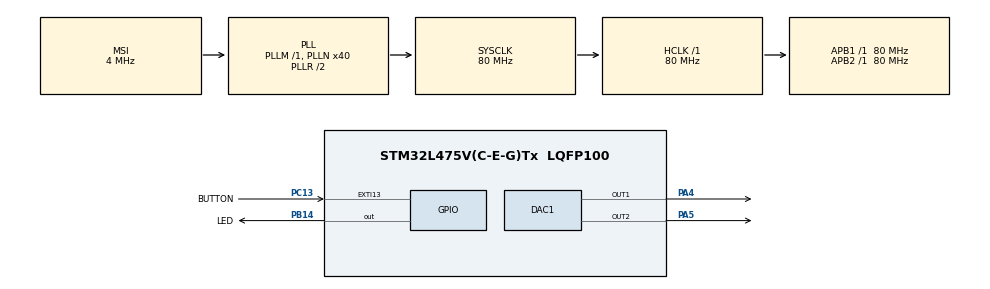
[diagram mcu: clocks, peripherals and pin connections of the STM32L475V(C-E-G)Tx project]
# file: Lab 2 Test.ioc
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Mcu.Family=STM32L4
RCC.MSI_VALUE=4000000
RCC.CortexFreq_Value=80000000
DAC1.DAC_Channel-DAC_OUT2=DAC_CHANNEL_2
SH.COMP_DAC12_group.0=DAC1_OUT2,DAC_OUT2
PC13.Signal=GPXTI13
PB14.GPIO_Label=LED
PC13.GPIO_Label=BUTTON
RCC.SYSCLKSource=RCC_SYSCLKSOURCE_PLLCLK
ProjectManager.StackSize=0x400
PB3\ (JTDO-TRACESWO).Signal=SYS_JTDO-SWO
ProjectManager.TargetToolchain=STM32CubeIDE
SH.COMP_DAC11_group.0=DAC1_OUT1,DAC_OUT1
RCC.HCLKFreq_Value=80000000
RCC.APB2TimFreq_Value=80000000
RCC.USBFreq_Value=48000000
RCC.LSE_VALUE=32768
RCC.AHBFreq_Value=80000000
PB14.Signal=GPIO_Output
PA5.Signal=COMP_DAC12_group
RCC.HSE_VALUE=8000000
board=B-L475E-IOT01A1
RCC.VCOOutputFreq_Value=160000000
RCC.APB2Freq_Value=80000000
RCC.ADCFreq_Value=48000000
Mcu.Name=STM32L475V(C-E-G)Tx
PA4.Signal=COMP_DAC11_group
RCC.SYSCLKFreq_VALUE=80000000
Mcu.Package=LQFP100
ProjectManager.HeapSize=0x200
RCC.HSI_VALUE=16000000
NVIC.PriorityGroup=NVIC_PRIORITYGROUP_4
RCC.PLLN=40
RCC.APB1TimFreq_Value=80000000
PA13\ (JTMS-SWDIO).Signal=SYS_JTMS-SWDIO
RCC.APB1Freq_Value=80000000
RCC.PLLSAI1N=24

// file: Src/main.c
/* USER CODE BEGIN Header */
/**
  ******************************************************************************
  * @file           : main.c
  * @brief          : Main program body
  ******************************************************************************
  * @attention
  *
  * <h2><center>&copy; Copyright (c) 2020 STMicroelectronics.
  * All rights reserved.</center></h2>
  *
  * This software component is licensed by ST under BSD 3-Clause license,
  * the "License"; You may not use this file except in compliance with the
  * License. You may obtain a copy of the License at:
  *                        opensource.org/licenses/BSD-3-Clause
  *
  ******************************************************************************
  */
/* USER CODE END Header */
#include "main.h"

/* USER CODE BEGIN Includes */
#define ARM_MATH_CM4
#include "arm_math.h"

#include <math.h>
/* USER CODE END Includes */

DAC_HandleTypeDef hdac1;

void SystemClock_Config(void);
static void MX_GPIO_Init(void);
static void MX_DAC1_Init(void);

int main(void)
{

  /* MCU Configuration--------------------------------------------------------*/

  /* Reset of all peripherals, Initializes the Flash interface and the Systick. */
  HAL_Init();

  /* Configure the system clock */
  SystemClock_Config();

  /* Initialize all configured peripherals */
  MX_GPIO_Init();
  MX_DAC1_Init();

  /* Infinite loop */
  while (1)
  {

    /* USER CODE BEGIN 3 */
	HAL_GPIO_TogglePin(GPIOA, GPIO_PIN_4);
	HAL_Delay(1);
  }
  /* USER CODE END 3 */
}

void SystemClock_Config(void)
{
  RCC_OscInitTypeDef RCC_OscInitStruct = {0};
  RCC_ClkInitTypeDef RCC_ClkInitStruct = {0};

  /** Initializes the RCC Oscillators according to the specified parameters
  * in the RCC_OscInitTypeDef structure.
  */
  RCC_OscInitStruct.OscillatorType = RCC_OSCILLATORTYPE_MSI;
  RCC_OscInitStruct.MSIState = RCC_MSI_ON;
  RCC_OscInitStruct.MSICalibrationValue = 0;
  RCC_OscInitStruct.MSIClockRange = RCC_MSIRANGE_6;
  RCC_OscInitStruct.PLL.PLLState = RCC_PLL_ON;
  RCC_OscInitStruct.PLL.PLLSource = RCC_PLLSOURCE_MSI;
  RCC_OscInitStruct.PLL.PLLM = 1;
  RCC_OscInitStruct.PLL.PLLN = 40;
  RCC_OscInitStruct.PLL.PLLP = RCC_PLLP_DIV7;
  RCC_OscInitStruct.PLL.PLLQ = RCC_PLLQ_DIV2;
  RCC_OscInitStruct.PLL.PLLR = RCC_PLLR_DIV2;
  if (HAL_RCC_OscConfig(&RCC_OscInitStruct) != HAL_OK)
  {
    Error_Handler();
  }
  /** Initializes the CPU, AHB and APB buses clocks
  */
  RCC_ClkInitStruct.ClockType = RCC_CLOCKTYPE_HCLK|RCC_CLOCKTYPE_SYSCLK
                              |RCC_CLOCKTYPE_PCLK1|RCC_CLOCKTYPE_PCLK2;
  RCC_ClkInitStruct.SYSCLKSource = RCC_SYSCLKSOURCE_PLLCLK;
  RCC_ClkInitStruct.AHBCLKDivider = RCC_SYSCLK_DIV1;
  RCC_ClkInitStruct.APB1CLKDivider = RCC_HCLK_DIV1;
  RCC_ClkInitStruct.APB2CLKDivider = RCC_HCLK_DIV1;

  if (HAL_RCC_ClockConfig(&RCC_ClkInitStruct, FLASH_LATENCY_4) != HAL_OK)
  {
    Error_Handler();
  }
  /** Configure the main internal regulator output voltage
  */
  if (HAL_PWREx_ControlVoltageScaling(PWR_REGULATOR_VOLTAGE_SCALE1) != HAL_OK)
  {
    Error_Handler();
  }
}

static void MX_DAC1_Init(void)
{

  DAC_ChannelConfTypeDef sConfig = {0};

  /** DAC Initialization
  */
  hdac1.Instance = DAC1;
  if (HAL_DAC_Init(&hdac1) != HAL_OK)
  {
    Error_Handler();
  }
  /** DAC channel OUT1 config
  */
  sConfig.DAC_SampleAndHold = DAC_SAMPLEANDHOLD_DISABLE;
  sConfig.DAC_Trigger = DAC_TRIGGER_NONE;
  sConfig.DAC_OutputBuffer = DAC_OUTPUTBUFFER_ENABLE;
  sConfig.DAC_ConnectOnChipPeripheral = DAC_CHIPCONNECT_DISABLE;
  sConfig.DAC_UserTrimming = DAC_TRIMMING_FACTORY;
  if (HAL_DAC_ConfigChannel(&hdac1, &sConfig, DAC_CHANNEL_1) != HAL_OK)
  {
    Error_Handler();
  }
  /** DAC channel OUT2 config
  */
  sConfig.DAC_ConnectOnChipPeripheral = DAC_CHIPCONNECT_DISABLE;
  if (HAL_DAC_ConfigChannel(&hdac1, &sConfig, DAC_CHANNEL_2) != HAL_OK)
  {
    Error_Handler();
  }

}

static void MX_GPIO_Init(void)
{
  GPIO_InitTypeDef GPIO_InitStruct = {0};

  /* GPIO Ports Clock Enable */
  __HAL_RCC_GPIOC_CLK_ENABLE();
  __HAL_RCC_GPIOA_CLK_ENABLE();
  __HAL_RCC_GPIOB_CLK_ENABLE();

  /*Configure GPIO pin Output Level */
  HAL_GPIO_WritePin(LED_GPIO_Port, LED_Pin, GPIO_PIN_RESET);

  /*Configure GPIO pin : BUTTON_Pin */
  GPIO_InitStruct.Pin = BUTTON_Pin;
  GPIO_InitStruct.Mode = GPIO_MODE_IT_RISING;
  GPIO_InitStruct.Pull = GPIO_NOPULL;
  HAL_GPIO_Init(BUTTON_GPIO_Port, &GPIO_InitStruct);

  /*Configure GPIO pin : LED_Pin */
  GPIO_InitStruct.Pin = LED_Pin;
  GPIO_InitStruct.Mode = GPIO_MODE_OUTPUT_PP;
  GPIO_InitStruct.Pull = GPIO_NOPULL;
  GPIO_InitStruct.Speed = GPIO_SPEED_FREQ_LOW;
  HAL_GPIO_Init(LED_GPIO_Port, &GPIO_InitStruct);

}

void Error_Handler(void)
{
}

/************************ (C) COPYRIGHT STMicroelectronics *****END OF FILE****/
